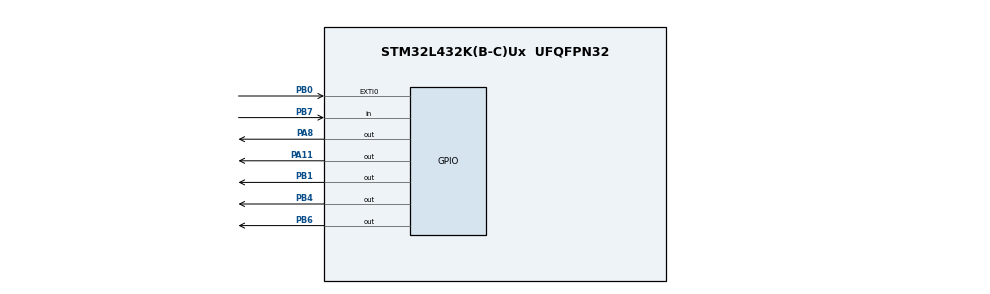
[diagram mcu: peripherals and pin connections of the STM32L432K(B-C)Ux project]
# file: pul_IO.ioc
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Mcu.Family=STM32L4
Mcu.Name=STM32L432K(B-C)Ux
Mcu.Package=UFQFPN32
NVIC.PriorityGroup=NVIC_PRIORITYGROUP_4
PA11.Signal=GPIO_Output
PA8.Signal=GPIO_Output
PB0.GPIO_PuPd=GPIO_PULLDOWN
PB0.Signal=GPXTI0
PB1.Signal=GPIO_Output
PB4\ (NJTRST).Signal=GPIO_Output
PB6.Signal=GPIO_Output
PB7.GPIO_PuPd=GPIO_PULLDOWN
PB7.Signal=GPIO_Input
ProjectManager.HeapSize=0x200
ProjectManager.StackSize=0x400
ProjectManager.TargetToolchain=STM32CubeIDE
RCC.HSE_VALUE=8000000
RCC.HSI48_VALUE=48000000
RCC.HSI_VALUE=16000000
RCC.LSE_VALUE=32768
RCC.MSI_VALUE=4000000
RCC.VCOOutputFreq_Value=32000000
board=custom

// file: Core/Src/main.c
/* USER CODE BEGIN Header */
/**
  ******************************************************************************
  * @file           : main.c
  * @brief          : Main program body
  ******************************************************************************
  * @attention
  *
  * <h2><center>&copy; Copyright (c) 2022 STMicroelectronics.
  * All rights reserved.</center></h2>
  *
  * This software component is licensed by ST under BSD 3-Clause license,
  * the "License"; You may not use this file except in compliance with the
  * License. You may obtain a copy of the License at:
  *                        opensource.org/licenses/BSD-3-Clause
  *
  ******************************************************************************
  */
/* USER CODE END Header */
#include "main.h"

/* USER CODE BEGIN PD */
int bot=1;
/* USER CODE END PD */

void SystemClock_Config(void);
static void MX_GPIO_Init(void);

int main(void)
{

  /* MCU Configuration--------------------------------------------------------*/

  /* Reset of all peripherals, Initializes the Flash interface and the Systick. */
  HAL_Init();

  /* Configure the system clock */
  SystemClock_Config();

  /* Initialize all configured peripherals */
  MX_GPIO_Init();

  /* Infinite loop */
  while (1)
  {
	  if((HAL_GPIO_ReadPin(GPIOB,GPIO_PIN_7))==1){
		  		  while (1){
		  			  if((HAL_GPIO_ReadPin(GPIOB,GPIO_PIN_7))==0){
		  				  bot=bot+1;
		  				  HAL_GPIO_WritePin(GPIOB, GPIO_PIN_4, 1);
		  				HAL_Delay(300);
		  				  break;
		  			  }
		  		  }
		  	  }
	  HAL_GPIO_WritePin(GPIOB, GPIO_PIN_4, 0);
	  HAL_GPIO_WritePin(GPIOB, GPIO_PIN_6, 1);
	  HAL_Delay(1000-(bot*100));

	  HAL_GPIO_WritePin(GPIOB, GPIO_PIN_6, 0);
	  HAL_GPIO_WritePin(GPIOB, GPIO_PIN_1, 1);
	  HAL_Delay(1000-(bot*100));

	  HAL_GPIO_WritePin(GPIOB, GPIO_PIN_1, 0);
	  HAL_GPIO_WritePin(GPIOA, GPIO_PIN_8, 1);
	  HAL_Delay(1000-(bot*100));

	  HAL_GPIO_WritePin(GPIOA, GPIO_PIN_8, 0);
	  HAL_GPIO_WritePin(GPIOA, GPIO_PIN_11, 1);
	  HAL_Delay(1000-(bot*100));
	  HAL_GPIO_WritePin(GPIOA, GPIO_PIN_11, 0);

		  	  if(bot>=10){
		  		  bot=1;
		  	  }
  }
}

void SystemClock_Config(void)
{
  RCC_OscInitTypeDef RCC_OscInitStruct = {0};
  RCC_ClkInitTypeDef RCC_ClkInitStruct = {0};

  /** Initializes the RCC Oscillators according to the specified parameters
  * in the RCC_OscInitTypeDef structure.
  */
  RCC_OscInitStruct.OscillatorType = RCC_OSCILLATORTYPE_MSI;
  RCC_OscInitStruct.MSIState = RCC_MSI_ON;
  RCC_OscInitStruct.MSICalibrationValue = 0;
  RCC_OscInitStruct.MSIClockRange = RCC_MSIRANGE_6;
  RCC_OscInitStruct.PLL.PLLState = RCC_PLL_NONE;
  if (HAL_RCC_OscConfig(&RCC_OscInitStruct) != HAL_OK)
  {
    Error_Handler();
  }
  /** Initializes the CPU, AHB and APB buses clocks
  */
  RCC_ClkInitStruct.ClockType = RCC_CLOCKTYPE_HCLK|RCC_CLOCKTYPE_SYSCLK
                              |RCC_CLOCKTYPE_PCLK1|RCC_CLOCKTYPE_PCLK2;
  RCC_ClkInitStruct.SYSCLKSource = RCC_SYSCLKSOURCE_MSI;
  RCC_ClkInitStruct.AHBCLKDivider = RCC_SYSCLK_DIV1;
  RCC_ClkInitStruct.APB1CLKDivider = RCC_HCLK_DIV1;
  RCC_ClkInitStruct.APB2CLKDivider = RCC_HCLK_DIV1;

  if (HAL_RCC_ClockConfig(&RCC_ClkInitStruct, FLASH_LATENCY_0) != HAL_OK)
  {
    Error_Handler();
  }
  /** Configure the main internal regulator output voltage
  */
  if (HAL_PWREx_ControlVoltageScaling(PWR_REGULATOR_VOLTAGE_SCALE1) != HAL_OK)
  {
    Error_Handler();
  }
}

static void MX_GPIO_Init(void)
{
  GPIO_InitTypeDef GPIO_InitStruct = {0};

  /* GPIO Ports Clock Enable */
  __HAL_RCC_GPIOB_CLK_ENABLE();
  __HAL_RCC_GPIOA_CLK_ENABLE();

  /*Configure GPIO pin Output Level */
  HAL_GPIO_WritePin(GPIOB, GPIO_PIN_1|GPIO_PIN_4|GPIO_PIN_6, GPIO_PIN_RESET);

  /*Configure GPIO pin Output Level */
  HAL_GPIO_WritePin(GPIOA, GPIO_PIN_8|GPIO_PIN_11, GPIO_PIN_RESET);

  /*Configure GPIO pin : PB0 */
  GPIO_InitStruct.Pin = GPIO_PIN_0;
  GPIO_InitStruct.Mode = GPIO_MODE_IT_RISING;
  GPIO_InitStruct.Pull = GPIO_PULLDOWN;
  HAL_GPIO_Init(GPIOB, &GPIO_InitStruct);

  /*Configure GPIO pins : PB1 PB4 PB6 */
  GPIO_InitStruct.Pin = GPIO_PIN_1|GPIO_PIN_4|GPIO_PIN_6;
  GPIO_InitStruct.Mode = GPIO_MODE_OUTPUT_PP;
  GPIO_InitStruct.Pull = GPIO_NOPULL;
  GPIO_InitStruct.Speed = GPIO_SPEED_FREQ_LOW;
  HAL_GPIO_Init(GPIOB, &GPIO_InitStruct);

  /*Configure GPIO pins : PA8 PA11 */
  GPIO_InitStruct.Pin = GPIO_PIN_8|GPIO_PIN_11;
  GPIO_InitStruct.Mode = GPIO_MODE_OUTPUT_PP;
  GPIO_InitStruct.Pull = GPIO_NOPULL;
  GPIO_InitStruct.Speed = GPIO_SPEED_FREQ_LOW;
  HAL_GPIO_Init(GPIOA, &GPIO_InitStruct);

  /*Configure GPIO pin : PB7 */
  GPIO_InitStruct.Pin = GPIO_PIN_7;
  GPIO_InitStruct.Mode = GPIO_MODE_INPUT;
  GPIO_InitStruct.Pull = GPIO_PULLDOWN;
  HAL_GPIO_Init(GPIOB, &GPIO_InitStruct);

}

void Error_Handler(void)
{
  __disable_irq();
  while (1)
  {
  }
}

/************************ (C) COPYRIGHT STMicroelectronics *****END OF FILE****/
